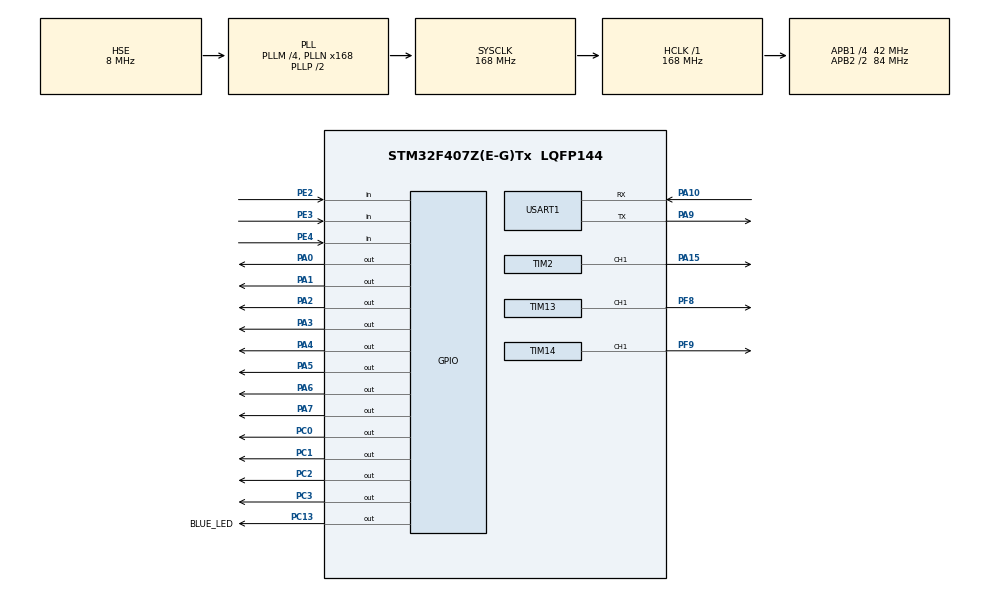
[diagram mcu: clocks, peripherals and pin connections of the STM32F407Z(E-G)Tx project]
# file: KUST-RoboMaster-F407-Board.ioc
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Dma.Request0=USART1_RX
Dma.Request1=USART1_TX
Dma.USART1_RX.0.Direction=DMA_PERIPH_TO_MEMORY
Dma.USART1_RX.0.FIFOMode=DMA_FIFOMODE_DISABLE
Dma.USART1_RX.0.Instance=DMA2_Stream2
Dma.USART1_RX.0.MemDataAlignment=DMA_MDATAALIGN_BYTE
Dma.USART1_RX.0.MemInc=DMA_MINC_ENABLE
Dma.USART1_RX.0.Mode=DMA_NORMAL
Dma.USART1_RX.0.PeriphDataAlignment=DMA_PDATAALIGN_BYTE
Dma.USART1_RX.0.PeriphInc=DMA_PINC_DISABLE
Dma.USART1_RX.0.Priority=DMA_PRIORITY_LOW
Dma.USART1_TX.1.Direction=DMA_MEMORY_TO_PERIPH
Dma.USART1_TX.1.FIFOMode=DMA_FIFOMODE_DISABLE
Dma.USART1_TX.1.Instance=DMA2_Stream7
Dma.USART1_TX.1.MemDataAlignment=DMA_MDATAALIGN_BYTE
Dma.USART1_TX.1.MemInc=DMA_MINC_ENABLE
Dma.USART1_TX.1.Mode=DMA_NORMAL
Dma.USART1_TX.1.PeriphDataAlignment=DMA_PDATAALIGN_BYTE
Dma.USART1_TX.1.PeriphInc=DMA_PINC_DISABLE
Dma.USART1_TX.1.Priority=DMA_PRIORITY_LOW
Mcu.Family=STM32F4
Mcu.Name=STM32F407Z(E-G)Tx
Mcu.Package=LQFP144
NVIC.DMA2_Stream2_IRQn=true\:0\:0\:false\:false\:true\:false\:true\:true
NVIC.DMA2_Stream7_IRQn=true\:0\:0\:false\:false\:true\:false\:true\:true
NVIC.PriorityGroup=NVIC_PRIORITYGROUP_4
NVIC.TIM1_UP_TIM10_IRQn=true\:0\:0\:false\:false\:true\:true\:true\:true
NVIC.USART1_IRQn=true\:0\:0\:false\:false\:true\:true\:true\:true
PA0-WKUP.Signal=GPIO_Output
PA1.Signal=GPIO_Output
PA10.Mode=Asynchronous
PA10.Signal=USART1_RX
PA13.Mode=Serial_Wire
PA13.Signal=SYS_JTMS-SWDIO
PA14.Mode=Serial_Wire
PA14.Signal=SYS_JTCK-SWCLK
PA15.Signal=S_TIM2_CH1_ETR
PA2.Signal=GPIO_Output
PA3.Signal=GPIO_Output
PA4.Signal=GPIO_Output
PA5.Signal=GPIO_Output
PA6.Signal=GPIO_Output
PA7.Signal=GPIO_Output
PA9.Mode=Asynchronous
PA9.Signal=USART1_TX
PC0.Signal=GPIO_Output
PC1.Signal=GPIO_Output
PC13-ANTI_TAMP.GPIO_Label=BLUE_LED
PC13-ANTI_TAMP.Signal=GPIO_Output
PC14-OSC32_IN.Mode=LSE-External-Oscillator
PC14-OSC32_IN.Signal=RCC_OSC32_IN
PC15-OSC32_OUT.Mode=LSE-External-Oscillator
PC15-OSC32_OUT.Signal=RCC_OSC32_OUT
PC2.Signal=GPIO_Output
PC3.Signal=GPIO_Output
PE2.GPIO_PuPd=GPIO_PULLUP
PE2.Signal=GPIO_Input
PE3.GPIO_PuPd=GPIO_PULLUP
PE3.Signal=GPIO_Input
PE4.GPIO_PuPd=GPIO_PULLUP
PE4.Signal=GPIO_Input
PF8.GPIO_PuPd=GPIO_NOPULL
PF8.Signal=S_TIM13_CH1
PF9.Signal=S_TIM14_CH1
PH0-OSC_IN.Mode=HSE-External-Oscillator
PH0-OSC_IN.Signal=RCC_OSC_IN
PH1-OSC_OUT.Mode=HSE-External-Oscillator
PH1-OSC_OUT.Signal=RCC_OSC_OUT
ProjectManager.HeapSize=0x200
ProjectManager.StackSize=0x400
ProjectManager.TargetToolchain=STM32CubeIDE
RCC.48MHZClocksFreq_Value=84000000
RCC.AHBFreq_Value=168000000
RCC.APB1CLKDivider=RCC_HCLK_DIV4
RCC.APB1Freq_Value=42000000
RCC.APB1TimFreq_Value=84000000
RCC.APB2CLKDivider=RCC_HCLK_DIV2
RCC.APB2Freq_Value=84000000
RCC.APB2TimFreq_Value=168000000
RCC.CortexFreq_Value=168000000
RCC.HCLKFreq_Value=168000000
RCC.HSE_VALUE=8000000
RCC.HSI_VALUE=16000000
RCC.PLLM=4
RCC.PLLN=168
RCC.PLLSourceVirtual=RCC_PLLSOURCE_HSE
RCC.SYSCLKFreq_VALUE=168000000
RCC.SYSCLKSource=RCC_SYSCLKSOURCE_PLLCLK
RCC.VCOOutputFreq_Value=336000000
SH.S_TIM13_CH1.0=TIM13_CH1,PWM Generation1 CH1
SH.S_TIM14_CH1.0=TIM14_CH1,PWM Generation1 CH1
SH.S_TIM2_CH1_ETR.0=TIM2_CH1,PWM Generation1 CH1
TIM1.AutoReloadPreload=TIM_AUTORELOAD_PRELOAD_ENABLE
TIM1.Period=168-1
TIM1.Prescaler=0
TIM13.AutoReloadPreload=TIM_AUTORELOAD_PRELOAD_ENABLE
TIM13.Channel=TIM_CHANNEL_1
TIM13.Period=1000
TIM13.Prescaler=42
TIM13.Pulse=0
TIM14.AutoReloadPreload=TIM_AUTORELOAD_PRELOAD_ENABLE
TIM14.Channel=TIM_CHANNEL_1
TIM14.Period=1000
TIM14.Prescaler=42
TIM2.AutoReloadPreload=TIM_AUTORELOAD_PRELOAD_ENABLE
TIM2.Channel-PWM\ Generation1\ CH1=TIM_CHANNEL_1
TIM2.Period=10000-1
TIM2.Prescaler=168-1
TIM2.Pulse-PWM\ Generation1\ CH1=3000-1
USART1.VirtualMode=VM_ASYNC
VP_TIM13_VS_ClockSourceINT.Mode=Enable_Timer
VP_TIM14_VS_ClockSourceINT.Mode=Enable_Timer
VP_TIM1_VS_ClockSourceINT.Mode=Internal
VP_TIM2_VS_ClockSourceINT.Mode=Internal
board=custom

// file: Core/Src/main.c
/* USER CODE BEGIN Header */
/**
  ******************************************************************************
  * @file           : main.c
  * @brief          : Main program body
  ******************************************************************************
  * @attention
  *
  * Copyright (c) 2026 STMicroelectronics.
  * All rights reserved.
  *
  * This software is licensed under terms that can be found in the LICENSE file
  * in the root directory of this software component.
  * If no LICENSE file comes with this software, it is provided AS-IS.
  *
  ******************************************************************************
  */
/* USER CODE END Header */
#include "main.h"

/* USER CODE BEGIN Includes */
#include  "bsp.h"
#include "../../User_Lib/user_music.h"

/* USER CODE END Includes */

TIM_HandleTypeDef htim1;
TIM_HandleTypeDef htim2;
TIM_HandleTypeDef htim13;
TIM_HandleTypeDef htim14;

UART_HandleTypeDef huart1;
DMA_HandleTypeDef hdma_usart1_rx;
DMA_HandleTypeDef hdma_usart1_tx;

void SystemClock_Config(void);
static void MX_GPIO_Init(void);
static void MX_DMA_Init(void);
static void MX_USART1_UART_Init(void);
static void MX_TIM1_Init(void);
static void MX_TIM2_Init(void);
static void MX_TIM13_Init(void);
static void MX_TIM14_Init(void);

int main(void)
{

  /* MCU Configuration--------------------------------------------------------*/

  /* Reset of all peripherals, Initializes the Flash interface and the Systick. */
  HAL_Init();

  /* Configure the system clock */
  SystemClock_Config();

  /* Initialize all configured peripherals */
  MX_GPIO_Init();
  MX_DMA_Init();
  MX_USART1_UART_Init();
  MX_TIM1_Init();
  MX_TIM2_Init();
  MX_TIM13_Init();
  MX_TIM14_Init();
  /* USER CODE BEGIN 2 */

  // 初始化蜂鸣器
  Buzzer_Init(&user_buzzer_1, &htim13, TIM_CHANNEL_1, 84000000);

  // 初始化启动音乐
  StartupMusic_Init(&user_startup_music, &user_buzzer_1, &user_startup_music_task, bad_apple, sizeof(bad_apple) / sizeof(bad_apple[0]));

  LED_Init(&user_led, GPIOF, GPIO_PIN_9, 1);
  SysTick_InitTask(&LED_Blink_Task, &user_led, 10, 800, Task_REPEAT, LED_Blink_Callback);
  SysTick_StartTask(&LED_Blink_Task);

  PWM_Init(&user_pwm_1, &htim14, TIM_CHANNEL_1, 84000000);
  PWM_Set_Frequency(&user_pwm_1, 1000);

  UART_Init(&user_uart_debug, &huart1);

  /* USER CODE END 2 */

  /* Infinite loop */
  while (1)
  {

    /* USER CODE BEGIN 3 */
    LOOP_EVENT_Handle();
  }
  /* USER CODE END 3 */
}

void SystemClock_Config(void)
{
  RCC_OscInitTypeDef RCC_OscInitStruct = {0};
  RCC_ClkInitTypeDef RCC_ClkInitStruct = {0};

  /** Configure the main internal regulator output voltage
  */
  __HAL_RCC_PWR_CLK_ENABLE();
  __HAL_PWR_VOLTAGESCALING_CONFIG(PWR_REGULATOR_VOLTAGE_SCALE1);

  /** Initializes the RCC Oscillators according to the specified parameters
  * in the RCC_OscInitTypeDef structure.
  */
  RCC_OscInitStruct.OscillatorType = RCC_OSCILLATORTYPE_HSE;
  RCC_OscInitStruct.HSEState = RCC_HSE_ON;
  RCC_OscInitStruct.PLL.PLLState = RCC_PLL_ON;
  RCC_OscInitStruct.PLL.PLLSource = RCC_PLLSOURCE_HSE;
  RCC_OscInitStruct.PLL.PLLM = 4;
  RCC_OscInitStruct.PLL.PLLN = 168;
  RCC_OscInitStruct.PLL.PLLP = RCC_PLLP_DIV2;
  RCC_OscInitStruct.PLL.PLLQ = 4;
  if (HAL_RCC_OscConfig(&RCC_OscInitStruct) != HAL_OK)
  {
    Error_Handler();
  }

  /** Initializes the CPU, AHB and APB buses clocks
  */
  RCC_ClkInitStruct.ClockType = RCC_CLOCKTYPE_HCLK|RCC_CLOCKTYPE_SYSCLK
                              |RCC_CLOCKTYPE_PCLK1|RCC_CLOCKTYPE_PCLK2;
  RCC_ClkInitStruct.SYSCLKSource = RCC_SYSCLKSOURCE_PLLCLK;
  RCC_ClkInitStruct.AHBCLKDivider = RCC_SYSCLK_DIV1;
  RCC_ClkInitStruct.APB1CLKDivider = RCC_HCLK_DIV4;
  RCC_ClkInitStruct.APB2CLKDivider = RCC_HCLK_DIV2;

  if (HAL_RCC_ClockConfig(&RCC_ClkInitStruct, FLASH_LATENCY_5) != HAL_OK)
  {
    Error_Handler();
  }
}

static void MX_TIM1_Init(void)
{

  TIM_ClockConfigTypeDef sClockSourceConfig = {0};
  TIM_MasterConfigTypeDef sMasterConfig = {0};

  htim1.Instance = TIM1;
  htim1.Init.Prescaler = 0;
  htim1.Init.CounterMode = TIM_COUNTERMODE_UP;
  htim1.Init.Period = 168-1;
  htim1.Init.ClockDivision = TIM_CLOCKDIVISION_DIV1;
  htim1.Init.RepetitionCounter = 0;
  htim1.Init.AutoReloadPreload = TIM_AUTORELOAD_PRELOAD_ENABLE;
  if (HAL_TIM_Base_Init(&htim1) != HAL_OK)
  {
    Error_Handler();
  }
  sClockSourceConfig.ClockSource = TIM_CLOCKSOURCE_INTERNAL;
  if (HAL_TIM_ConfigClockSource(&htim1, &sClockSourceConfig) != HAL_OK)
  {
    Error_Handler();
  }
  sMasterConfig.MasterOutputTrigger = TIM_TRGO_RESET;
  sMasterConfig.MasterSlaveMode = TIM_MASTERSLAVEMODE_DISABLE;
  if (HAL_TIMEx_MasterConfigSynchronization(&htim1, &sMasterConfig) != HAL_OK)
  {
    Error_Handler();
  }

}

static void MX_TIM2_Init(void)
{

  TIM_ClockConfigTypeDef sClockSourceConfig = {0};
  TIM_MasterConfigTypeDef sMasterConfig = {0};
  TIM_OC_InitTypeDef sConfigOC = {0};

  htim2.Instance = TIM2;
  htim2.Init.Prescaler = 168-1;
  htim2.Init.CounterMode = TIM_COUNTERMODE_UP;
  htim2.Init.Period = 10000-1;
  htim2.Init.ClockDivision = TIM_CLOCKDIVISION_DIV1;
  htim2.Init.AutoReloadPreload = TIM_AUTORELOAD_PRELOAD_ENABLE;
  if (HAL_TIM_Base_Init(&htim2) != HAL_OK)
  {
    Error_Handler();
  }
  sClockSourceConfig.ClockSource = TIM_CLOCKSOURCE_INTERNAL;
  if (HAL_TIM_ConfigClockSource(&htim2, &sClockSourceConfig) != HAL_OK)
  {
    Error_Handler();
  }
  if (HAL_TIM_PWM_Init(&htim2) != HAL_OK)
  {
    Error_Handler();
  }
  sMasterConfig.MasterOutputTrigger = TIM_TRGO_RESET;
  sMasterConfig.MasterSlaveMode = TIM_MASTERSLAVEMODE_DISABLE;
  if (HAL_TIMEx_MasterConfigSynchronization(&htim2, &sMasterConfig) != HAL_OK)
  {
    Error_Handler();
  }
  sConfigOC.OCMode = TIM_OCMODE_PWM1;
  sConfigOC.Pulse = 3000-1;
  sConfigOC.OCPolarity = TIM_OCPOLARITY_HIGH;
  sConfigOC.OCFastMode = TIM_OCFAST_DISABLE;
  if (HAL_TIM_PWM_ConfigChannel(&htim2, &sConfigOC, TIM_CHANNEL_1) != HAL_OK)
  {
    Error_Handler();
  }
  HAL_TIM_MspPostInit(&htim2);

}

static void MX_TIM13_Init(void)
{

  TIM_OC_InitTypeDef sConfigOC = {0};

  htim13.Instance = TIM13;
  htim13.Init.Prescaler = 42;
  htim13.Init.CounterMode = TIM_COUNTERMODE_UP;
  htim13.Init.Period = 1000;
  htim13.Init.ClockDivision = TIM_CLOCKDIVISION_DIV1;
  htim13.Init.AutoReloadPreload = TIM_AUTORELOAD_PRELOAD_ENABLE;
  if (HAL_TIM_Base_Init(&htim13) != HAL_OK)
  {
    Error_Handler();
  }
  if (HAL_TIM_PWM_Init(&htim13) != HAL_OK)
  {
    Error_Handler();
  }
  sConfigOC.OCMode = TIM_OCMODE_PWM1;
  sConfigOC.Pulse = 0;
  sConfigOC.OCPolarity = TIM_OCPOLARITY_HIGH;
  sConfigOC.OCFastMode = TIM_OCFAST_DISABLE;
  if (HAL_TIM_PWM_ConfigChannel(&htim13, &sConfigOC, TIM_CHANNEL_1) != HAL_OK)
  {
    Error_Handler();
  }
  HAL_TIM_MspPostInit(&htim13);

}

static void MX_TIM14_Init(void)
{

  TIM_OC_InitTypeDef sConfigOC = {0};

  htim14.Instance = TIM14;
  htim14.Init.Prescaler = 42;
  htim14.Init.CounterMode = TIM_COUNTERMODE_UP;
  htim14.Init.Period = 1000;
  htim14.Init.ClockDivision = TIM_CLOCKDIVISION_DIV1;
  htim14.Init.AutoReloadPreload = TIM_AUTORELOAD_PRELOAD_ENABLE;
  if (HAL_TIM_Base_Init(&htim14) != HAL_OK)
  {
    Error_Handler();
  }
  if (HAL_TIM_PWM_Init(&htim14) != HAL_OK)
  {
    Error_Handler();
  }
  sConfigOC.OCMode = TIM_OCMODE_PWM1;
  sConfigOC.Pulse = 0;
  sConfigOC.OCPolarity = TIM_OCPOLARITY_HIGH;
  sConfigOC.OCFastMode = TIM_OCFAST_DISABLE;
  if (HAL_TIM_PWM_ConfigChannel(&htim14, &sConfigOC, TIM_CHANNEL_1) != HAL_OK)
  {
    Error_Handler();
  }
  HAL_TIM_MspPostInit(&htim14);

}

static void MX_USART1_UART_Init(void)
{

  huart1.Instance = USART1;
  huart1.Init.BaudRate = 115200;
  huart1.Init.WordLength = UART_WORDLENGTH_8B;
  huart1.Init.StopBits = UART_STOPBITS_1;
  huart1.Init.Parity = UART_PARITY_NONE;
  huart1.Init.Mode = UART_MODE_TX_RX;
  huart1.Init.HwFlowCtl = UART_HWCONTROL_NONE;
  huart1.Init.OverSampling = UART_OVERSAMPLING_16;
  if (HAL_UART_Init(&huart1) != HAL_OK)
  {
    Error_Handler();
  }

}

static void MX_DMA_Init(void)
{

  /* DMA controller clock enable */
  __HAL_RCC_DMA2_CLK_ENABLE();

  /* DMA interrupt init */
  /* DMA2_Stream2_IRQn interrupt configuration */
  HAL_NVIC_SetPriority(DMA2_Stream2_IRQn, 0, 0);
  HAL_NVIC_EnableIRQ(DMA2_Stream2_IRQn);
  /* DMA2_Stream7_IRQn interrupt configuration */
  HAL_NVIC_SetPriority(DMA2_Stream7_IRQn, 0, 0);
  HAL_NVIC_EnableIRQ(DMA2_Stream7_IRQn);

}

static void MX_GPIO_Init(void)
{
  GPIO_InitTypeDef GPIO_InitStruct = {0};

  /* GPIO Ports Clock Enable */
  __HAL_RCC_GPIOE_CLK_ENABLE();
  __HAL_RCC_GPIOC_CLK_ENABLE();
  __HAL_RCC_GPIOF_CLK_ENABLE();
  __HAL_RCC_GPIOH_CLK_ENABLE();
  __HAL_RCC_GPIOA_CLK_ENABLE();

  /*Configure GPIO pin Output Level */
  HAL_GPIO_WritePin(GPIOC, BLUE_LED_Pin|GPIO_PIN_0|GPIO_PIN_1|GPIO_PIN_2
                          |GPIO_PIN_3, GPIO_PIN_RESET);

  /*Configure GPIO pin Output Level */
  HAL_GPIO_WritePin(GPIOA, GPIO_PIN_0|GPIO_PIN_1|GPIO_PIN_2|GPIO_PIN_3
                          |GPIO_PIN_4|GPIO_PIN_5|GPIO_PIN_6|GPIO_PIN_7, GPIO_PIN_RESET);

  /*Configure GPIO pins : PE2 PE3 PE4 */
  GPIO_InitStruct.Pin = GPIO_PIN_2|GPIO_PIN_3|GPIO_PIN_4;
  GPIO_InitStruct.Mode = GPIO_MODE_INPUT;
  GPIO_InitStruct.Pull = GPIO_PULLUP;
  HAL_GPIO_Init(GPIOE, &GPIO_InitStruct);

  /*Configure GPIO pins : BLUE_LED_Pin PC0 PC1 PC2
                           PC3 */
  GPIO_InitStruct.Pin = BLUE_LED_Pin|GPIO_PIN_0|GPIO_PIN_1|GPIO_PIN_2
                          |GPIO_PIN_3;
  GPIO_InitStruct.Mode = GPIO_MODE_OUTPUT_PP;
  GPIO_InitStruct.Pull = GPIO_NOPULL;
  GPIO_InitStruct.Speed = GPIO_SPEED_FREQ_LOW;
  HAL_GPIO_Init(GPIOC, &GPIO_InitStruct);

  /*Configure GPIO pins : PA0 PA1 PA2 PA3
                           PA4 PA5 PA6 PA7 */
  GPIO_InitStruct.Pin = GPIO_PIN_0|GPIO_PIN_1|GPIO_PIN_2|GPIO_PIN_3
                          |GPIO_PIN_4|GPIO_PIN_5|GPIO_PIN_6|GPIO_PIN_7;
  GPIO_InitStruct.Mode = GPIO_MODE_OUTPUT_PP;
  GPIO_InitStruct.Pull = GPIO_NOPULL;
  GPIO_InitStruct.Speed = GPIO_SPEED_FREQ_LOW;
  HAL_GPIO_Init(GPIOA, &GPIO_InitStruct);

}

void Error_Handler(void)
{
  __disable_irq();
  while (1)
  {
  }
}
